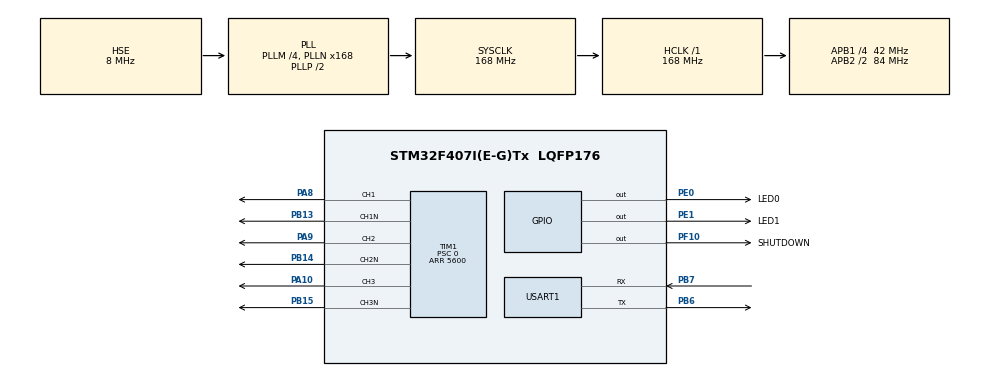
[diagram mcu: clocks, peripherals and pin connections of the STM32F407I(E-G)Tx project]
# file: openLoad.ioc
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Mcu.Family=STM32F4
Mcu.Name=STM32F407I(E-G)Tx
Mcu.Package=LQFP176
NVIC.PriorityGroup=NVIC_PRIORITYGROUP_4
NVIC.TIM6_DAC_IRQn=true\:0\:0\:false\:false\:true\:true\:true
PA10.Signal=S_TIM1_CH3
PA13.Mode=Serial_Wire
PA13.Signal=SYS_JTMS-SWDIO
PA14.Mode=Serial_Wire
PA14.Signal=SYS_JTCK-SWCLK
PA8.Signal=S_TIM1_CH1
PA9.Signal=S_TIM1_CH2
PB13.Mode=PWM Generation1 CH1 CH1N
PB13.Signal=TIM1_CH1N
PB14.Mode=PWM Generation2 CH2 CH2N
PB14.Signal=TIM1_CH2N
PB15.Mode=PWM Generation3 CH3 CH3N
PB15.Signal=TIM1_CH3N
PB6.Mode=Asynchronous
PB6.Signal=USART1_TX
PB7.Mode=Asynchronous
PB7.Signal=USART1_RX
PE0.GPIO_Label=LED0
PE0.GPIO_PuPd=GPIO_PULLUP
PE0.PinState=GPIO_PIN_SET
PE0.Signal=GPIO_Output
PE1.GPIO_Label=LED1
PE1.GPIO_PuPd=GPIO_PULLUP
PE1.PinState=GPIO_PIN_SET
PE1.Signal=GPIO_Output
PF10.GPIO_Label=SHUTDOWN
PF10.GPIO_PuPd=GPIO_PULLUP
PF10.PinState=GPIO_PIN_SET
PF10.Signal=GPIO_Output
PH0-OSC_IN.Mode=HSE-External-Oscillator
PH0-OSC_IN.Signal=RCC_OSC_IN
PH1-OSC_OUT.Mode=HSE-External-Oscillator
PH1-OSC_OUT.Signal=RCC_OSC_OUT
ProjectManager.HeapSize=0x200
ProjectManager.StackSize=0x400
ProjectManager.TargetToolchain=MDK-ARM V5.27
RCC.48MHZClocksFreq_Value=84000000
RCC.AHBFreq_Value=168000000
RCC.APB1CLKDivider=RCC_HCLK_DIV4
RCC.APB1Freq_Value=42000000
RCC.APB1TimFreq_Value=84000000
RCC.APB2CLKDivider=RCC_HCLK_DIV2
RCC.APB2Freq_Value=84000000
RCC.APB2TimFreq_Value=168000000
RCC.CortexFreq_Value=168000000
RCC.HCLKFreq_Value=168000000
RCC.HSE_VALUE=8000000
RCC.HSI_VALUE=16000000
RCC.LSE_VALUE=32768
RCC.PLLM=4
RCC.PLLN=168
RCC.PLLSourceVirtual=RCC_PLLSOURCE_HSE
RCC.SYSCLKFreq_VALUE=168000000
RCC.SYSCLKSource=RCC_SYSCLKSOURCE_PLLCLK
RCC.VCOOutputFreq_Value=336000000
SH.S_TIM1_CH1.0=TIM1_CH1,PWM Generation1 CH1 CH1N
SH.S_TIM1_CH2.0=TIM1_CH2,PWM Generation2 CH2 CH2N
SH.S_TIM1_CH3.0=TIM1_CH3,PWM Generation3 CH3 CH3N
TIM1.BreakPolarity=TIM_BREAKPOLARITY_LOW
TIM1.BreakState=TIM_BREAK_DISABLE
TIM1.Channel-PWM\ Generation1\ CH1\ CH1N=TIM_CHANNEL_1
TIM1.Channel-PWM\ Generation2\ CH2\ CH2N=TIM_CHANNEL_2
TIM1.Channel-PWM\ Generation3\ CH3\ CH3N=TIM_CHANNEL_3
TIM1.ClockDivision=TIM_CLOCKDIVISION_DIV1
TIM1.CounterMode=TIM_COUNTERMODE_CENTERALIGNED1
TIM1.DeadTime=20
TIM1.LockLevel=TIM_LOCKLEVEL_1
TIM1.OffStateIDLEMode=TIM_OSSI_DISABLE
TIM1.OffStateRunMode=TIM_OSSR_DISABLE
TIM1.Period=5600
TIM1.Prescaler=0
TIM1.RepetitionCounter=0
TIM6.Period=100-1
TIM6.Prescaler=1680-1
USART1.VirtualMode=VM_ASYNC
VP_TIM6_VS_ClockSourceINT.Mode=Enable_Timer
board=custom

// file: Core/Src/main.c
/* USER CODE BEGIN Header */
/**
  ******************************************************************************
  * @file           : main.c
  * @brief          : Main program body
  ******************************************************************************
  * @attention
  *
  * <h2><center>&copy; Copyright (c) 2024 STMicroelectronics.
  * All rights reserved.</center></h2>
  *
  * This software component is licensed by ST under BSD 3-Clause license,
  * the "License"; You may not use this file except in compliance with the
  * License. You may obtain a copy of the License at:
  *                        opensource.org/licenses/BSD-3-Clause
  *
  ******************************************************************************
  */
/* USER CODE END Header */
#include "main.h"
#include "tim.h"
#include "usart.h"
#include "gpio.h"

/* USER CODE BEGIN Includes */
#include "stdio.h"
#include "svpwm.h"
#include "foc.h"
/* USER CODE END Includes */

void SystemClock_Config(void);

int main(void)
{

  /* MCU Configuration--------------------------------------------------------*/

  /* Reset of all peripherals, Initializes the Flash interface and the Systick. */
  HAL_Init();

  /* Configure the system clock */
  SystemClock_Config();

  /* Initialize all configured peripherals */
  MX_GPIO_Init();
  MX_TIM1_Init();
  MX_TIM6_Init();
  MX_USART1_UART_Init();
  /* USER CODE BEGIN 2 */
	HAL_TIM_Base_Start_IT(&htim6);
	motor_init();
//	__HAL_TIM_SET_COMPARE(&htim1, TIM_CHANNEL_1,2500);
  /* USER CODE END 2 */

  /* Infinite loop */
  while (1)
  {

    /* USER CODE BEGIN 3 */
//		HAL_GPIO_WritePin(GPIOE, LED0_Pin|LED1_Pin, GPIO_PIN_RESET);
//		HAL_Delay(500);
//		HAL_GPIO_WritePin(GPIOE, LED0_Pin|LED1_Pin, GPIO_PIN_SET);
//		HAL_Delay(500);
		printf("%f,%f,%f\r\n", Ta, Tb, Tc);
  }
  /* USER CODE END 3 */
}

void SystemClock_Config(void)
{
  RCC_OscInitTypeDef RCC_OscInitStruct = {0};
  RCC_ClkInitTypeDef RCC_ClkInitStruct = {0};

  /** Configure the main internal regulator output voltage
  */
  __HAL_RCC_PWR_CLK_ENABLE();
  __HAL_PWR_VOLTAGESCALING_CONFIG(PWR_REGULATOR_VOLTAGE_SCALE1);
  /** Initializes the RCC Oscillators according to the specified parameters
  * in the RCC_OscInitTypeDef structure.
  */
  RCC_OscInitStruct.OscillatorType = RCC_OSCILLATORTYPE_HSE;
  RCC_OscInitStruct.HSEState = RCC_HSE_ON;
  RCC_OscInitStruct.PLL.PLLState = RCC_PLL_ON;
  RCC_OscInitStruct.PLL.PLLSource = RCC_PLLSOURCE_HSE;
  RCC_OscInitStruct.PLL.PLLM = 4;
  RCC_OscInitStruct.PLL.PLLN = 168;
  RCC_OscInitStruct.PLL.PLLP = RCC_PLLP_DIV2;
  RCC_OscInitStruct.PLL.PLLQ = 4;
  if (HAL_RCC_OscConfig(&RCC_OscInitStruct) != HAL_OK)
  {
    Error_Handler();
  }
  /** Initializes the CPU, AHB and APB buses clocks
  */
  RCC_ClkInitStruct.ClockType = RCC_CLOCKTYPE_HCLK|RCC_CLOCKTYPE_SYSCLK
                              |RCC_CLOCKTYPE_PCLK1|RCC_CLOCKTYPE_PCLK2;
  RCC_ClkInitStruct.SYSCLKSource = RCC_SYSCLKSOURCE_PLLCLK;
  RCC_ClkInitStruct.AHBCLKDivider = RCC_SYSCLK_DIV1;
  RCC_ClkInitStruct.APB1CLKDivider = RCC_HCLK_DIV4;
  RCC_ClkInitStruct.APB2CLKDivider = RCC_HCLK_DIV2;

  if (HAL_RCC_ClockConfig(&RCC_ClkInitStruct, FLASH_LATENCY_5) != HAL_OK)
  {
    Error_Handler();
  }
}

/* USER CODE BEGIN 4 */
int fputc(int ch, FILE *f)
{
	HAL_UART_Transmit(&huart1, (uint8_t *)&ch, 1, 0xFFFF);

	return ch;
}
/* USER CODE END 4 */

void Error_Handler(void)
{
  __disable_irq();
  while (1)
  {
  }
}

/************************ (C) COPYRIGHT STMicroelectronics *****END OF FILE****/
